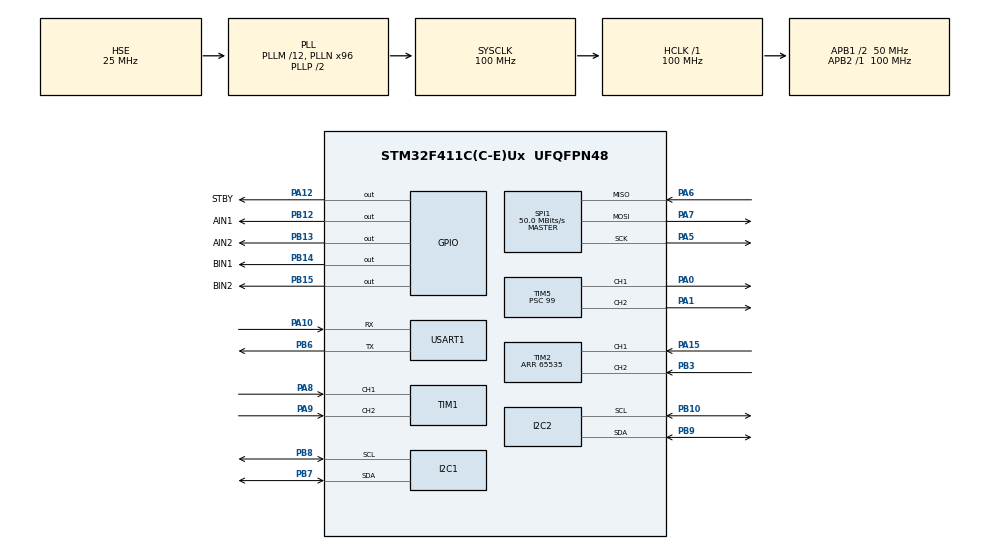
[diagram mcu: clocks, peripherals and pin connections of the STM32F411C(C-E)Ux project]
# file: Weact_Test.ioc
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Dma.I2C2_RX.2.Direction=DMA_PERIPH_TO_MEMORY
Dma.I2C2_RX.2.FIFOMode=DMA_FIFOMODE_DISABLE
Dma.I2C2_RX.2.Instance=DMA1_Stream2
Dma.I2C2_RX.2.MemDataAlignment=DMA_MDATAALIGN_BYTE
Dma.I2C2_RX.2.MemInc=DMA_MINC_ENABLE
Dma.I2C2_RX.2.Mode=DMA_CIRCULAR
Dma.I2C2_RX.2.PeriphDataAlignment=DMA_PDATAALIGN_BYTE
Dma.I2C2_RX.2.PeriphInc=DMA_PINC_DISABLE
Dma.I2C2_RX.2.Priority=DMA_PRIORITY_LOW
Dma.Request0=USART1_RX
Dma.Request1=USART1_TX
Dma.Request2=I2C2_RX
Dma.USART1_RX.0.Direction=DMA_PERIPH_TO_MEMORY
Dma.USART1_RX.0.FIFOMode=DMA_FIFOMODE_DISABLE
Dma.USART1_RX.0.Instance=DMA2_Stream2
Dma.USART1_RX.0.MemDataAlignment=DMA_MDATAALIGN_BYTE
Dma.USART1_RX.0.MemInc=DMA_MINC_ENABLE
Dma.USART1_RX.0.Mode=DMA_NORMAL
Dma.USART1_RX.0.PeriphDataAlignment=DMA_PDATAALIGN_BYTE
Dma.USART1_RX.0.PeriphInc=DMA_PINC_DISABLE
Dma.USART1_RX.0.Priority=DMA_PRIORITY_MEDIUM
Dma.USART1_TX.1.Direction=DMA_MEMORY_TO_PERIPH
Dma.USART1_TX.1.FIFOMode=DMA_FIFOMODE_DISABLE
Dma.USART1_TX.1.Instance=DMA2_Stream7
Dma.USART1_TX.1.MemDataAlignment=DMA_MDATAALIGN_BYTE
Dma.USART1_TX.1.MemInc=DMA_MINC_ENABLE
Dma.USART1_TX.1.Mode=DMA_NORMAL
Dma.USART1_TX.1.PeriphDataAlignment=DMA_PDATAALIGN_BYTE
Dma.USART1_TX.1.PeriphInc=DMA_PINC_DISABLE
Dma.USART1_TX.1.Priority=DMA_PRIORITY_MEDIUM
I2C2.I2C_Mode=I2C_Fast
Mcu.Family=STM32F4
Mcu.Name=STM32F411C(C-E)Ux
Mcu.Package=UFQFPN48
NVIC.DMA1_Stream2_IRQn=true\:0\:0\:false\:false\:true\:false\:true\:true
NVIC.DMA2_Stream2_IRQn=true\:0\:0\:false\:false\:true\:false\:true\:true
NVIC.DMA2_Stream7_IRQn=true\:0\:0\:false\:false\:true\:false\:true\:true
NVIC.PriorityGroup=NVIC_PRIORITYGROUP_4
NVIC.SPI1_IRQn=true\:2\:0\:true\:false\:true\:true\:true\:true
NVIC.TIM1_BRK_TIM9_IRQn=true\:0\:0\:false\:false\:true\:true\:true\:true
NVIC.TIM1_UP_TIM10_IRQn=true\:0\:0\:false\:false\:true\:true\:true\:true
NVIC.TIM2_IRQn=true\:0\:0\:false\:false\:true\:true\:true\:true
NVIC.TIM4_IRQn=true\:0\:0\:false\:false\:true\:true\:true\:true
NVIC.TIM5_IRQn=true\:0\:0\:true\:false\:true\:true\:true\:true
NVIC.USART1_IRQn=true\:2\:0\:true\:false\:true\:true\:true\:true
PA0-WKUP.Signal=S_TIM5_CH1
PA1.Signal=S_TIM5_CH2
PA10.Mode=Asynchronous
PA10.Signal=USART1_RX
PA12.GPIO_Label=STBY
PA12.GPIO_PuPd=GPIO_PULLUP
PA12.Signal=GPIO_Output
PA13.Mode=Serial_Wire
PA13.Signal=SYS_JTMS-SWDIO
PA14.Mode=Serial_Wire
PA14.Signal=SYS_JTCK-SWCLK
PA15.Signal=S_TIM2_CH1_ETR
PA4.GPIO_PuPd=GPIO_PULLUP
PA4.GPIO_Speed=GPIO_SPEED_FREQ_HIGH
PA4.Signal=SPI1_NSS
PA5.Mode=Full_Duplex_Master
PA5.Signal=SPI1_SCK
PA6.Mode=Full_Duplex_Master
PA6.Signal=SPI1_MISO
PA7.Mode=Full_Duplex_Master
PA7.Signal=SPI1_MOSI
PA8.Signal=S_TIM1_CH1
PA9.Signal=S_TIM1_CH2
PB10.Mode=I2C
PB10.Signal=I2C2_SCL
PB12.GPIO_Label=AIN1
PB12.GPIO_PuPd=GPIO_PULLUP
PB12.GPIO_Speed=GPIO_SPEED_FREQ_HIGH
PB12.Signal=GPIO_Output
PB13.GPIO_Label=AIN2
PB13.GPIO_PuPd=GPIO_PULLUP
PB13.GPIO_Speed=GPIO_SPEED_FREQ_HIGH
PB13.Signal=GPIO_Output
PB14.GPIO_Label=BIN1
PB14.GPIO_Speed=GPIO_SPEED_FREQ_HIGH
PB14.Signal=GPIO_Output
PB15.GPIO_Label=BIN2
PB15.GPIO_PuPd=GPIO_PULLUP
PB15.GPIO_Speed=GPIO_SPEED_FREQ_HIGH
PB15.Signal=GPIO_Output
PB3.Signal=S_TIM2_CH2
PB6.Mode=Asynchronous
PB6.Signal=USART1_TX
PB7.Mode=I2C
PB7.Signal=I2C1_SDA
PB8.Mode=I2C
PB8.Signal=I2C1_SCL
PB9.Mode=I2C
PB9.Signal=I2C2_SDA
PC14-OSC32_IN.Mode=LSE-External-Oscillator
PC14-OSC32_IN.Signal=RCC_OSC32_IN
PC15-OSC32_OUT.Mode=LSE-External-Oscillator
PC15-OSC32_OUT.Signal=RCC_OSC32_OUT
PH0\ -\ OSC_IN.Mode=HSE-External-Oscillator
PH0\ -\ OSC_IN.Signal=RCC_OSC_IN
PH1\ -\ OSC_OUT.Mode=HSE-External-Oscillator
PH1\ -\ OSC_OUT.Signal=RCC_OSC_OUT
ProjectManager.HeapSize=0x200
ProjectManager.StackSize=0x400
ProjectManager.TargetToolchain=MDK-ARM V5.32
RCC.48MHZClocksFreq_Value=50000000
RCC.AHBFreq_Value=100000000
RCC.APB1CLKDivider=RCC_HCLK_DIV2
RCC.APB1Freq_Value=50000000
RCC.APB1TimFreq_Value=100000000
RCC.APB2Freq_Value=100000000
RCC.APB2TimFreq_Value=100000000
RCC.CortexFreq_Value=100000000
RCC.HCLKFreq_Value=100000000
RCC.HSE_VALUE=25000000
RCC.HSI_VALUE=16000000
RCC.PLLM=12
RCC.PLLN=96
RCC.PLLSourceVirtual=RCC_PLLSOURCE_HSE
RCC.SYSCLKFreq_VALUE=100000000
RCC.SYSCLKSource=RCC_SYSCLKSOURCE_PLLCLK
RCC.VCOOutputFreq_Value=200000000
SH.S_TIM1_CH1.0=TIM1_CH1,Encoder_Interface
SH.S_TIM1_CH2.0=TIM1_CH2,Encoder_Interface
SH.S_TIM2_CH1_ETR.0=TIM2_CH1,Encoder_Interface
SH.S_TIM2_CH2.0=TIM2_CH2,Encoder_Interface
SH.S_TIM5_CH1.0=TIM5_CH1,PWM Generation1 CH1
SH.S_TIM5_CH2.0=TIM5_CH2,PWM Generation2 CH2
SPI1.CalculateBaudRate=50.0 MBits/s
SPI1.Direction=SPI_DIRECTION_2LINES
SPI1.Mode=SPI_MODE_MASTER
SPI1.VirtualType=VM_MASTER
TIM2.EncoderMode=TIM_ENCODERMODE_TI12
TIM2.Period=65535
TIM4.Period=10000
TIM4.Prescaler=99
TIM5.Channel-PWM\ Generation1\ CH1=TIM_CHANNEL_1
TIM5.Channel-PWM\ Generation2\ CH2=TIM_CHANNEL_2
TIM5.Period=99
TIM5.Prescaler=99
TIM9.Period=5000
TIM9.Prescaler=99
USART1.VirtualMode=VM_ASYNC
VP_TIM4_VS_ClockSourceINT.Mode=Internal
VP_TIM9_VS_ClockSourceINT.Mode=Internal
board=custom

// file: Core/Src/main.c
/* USER CODE BEGIN Header */
/**
  ******************************************************************************
  * @file           : main.c
  * @brief          : Main program body
  ******************************************************************************
  * @attention
  *
  * Copyright (c) 2023 STMicroelectronics.
  * All rights reserved.
  *
  * This software is licensed under terms that can be found in the LICENSE file
  * in the root directory of this software component.
  * If no LICENSE file comes with this software, it is provided AS-IS.
  *
  ******************************************************************************
  */
/* USER CODE END Header */
#include "main.h"
#include "dma.h"
#include "i2c.h"
#include "spi.h"
#include "tim.h"
#include "usart.h"
#include "gpio.h"

/* USER CODE BEGIN Includes */
#include "TB6612.h"
#include "pid.h"
/* USER CODE END Includes */

/* USER CODE BEGIN PM */
uint8_t RxDate[20]={0};
/* USER CODE END PM */

void SystemClock_Config(void);

int main(void)
{

  /* MCU Configuration--------------------------------------------------------*/

  /* Reset of all peripherals, Initializes the Flash interface and the Systick. */
  HAL_Init();

  /* Configure the system clock */
  SystemClock_Config();

  /* Initialize all configured peripherals */
  MX_GPIO_Init();
  MX_DMA_Init();
  MX_SPI1_Init();
  MX_TIM1_Init();
  MX_TIM2_Init();
  MX_USART1_UART_Init();
  MX_I2C1_Init();
  MX_I2C2_Init();
  MX_TIM5_Init();
  MX_TIM4_Init();
  MX_TIM9_Init();
  /* USER CODE BEGIN 2 */
	HAL_TIM_PWM_Init(&htim_pwm);
	HAL_GPIO_WritePin(STBY_GPIO_Port,STBY_Pin,GPIO_PIN_SET);
	HAL_GPIO_WritePin(AIN1_GPIO_Port,AIN1_Pin,GPIO_PIN_SET);
	HAL_GPIO_WritePin(AIN2_GPIO_Port,AIN2_Pin,GPIO_PIN_RESET);
	__HAL_TIM_SetCompare(&htim_pwm,channel_PWMA,99);

  /* USER CODE END 2 */

  /* Infinite loop */
  while (1)
  {

  }
}

void SystemClock_Config(void)
{
  RCC_OscInitTypeDef RCC_OscInitStruct = {0};
  RCC_ClkInitTypeDef RCC_ClkInitStruct = {0};

  /** Configure the main internal regulator output voltage
  */
  __HAL_RCC_PWR_CLK_ENABLE();
  __HAL_PWR_VOLTAGESCALING_CONFIG(PWR_REGULATOR_VOLTAGE_SCALE1);

  /** Initializes the RCC Oscillators according to the specified parameters
  * in the RCC_OscInitTypeDef structure.
  */
  RCC_OscInitStruct.OscillatorType = RCC_OSCILLATORTYPE_HSE;
  RCC_OscInitStruct.HSEState = RCC_HSE_ON;
  RCC_OscInitStruct.PLL.PLLState = RCC_PLL_ON;
  RCC_OscInitStruct.PLL.PLLSource = RCC_PLLSOURCE_HSE;
  RCC_OscInitStruct.PLL.PLLM = 12;
  RCC_OscInitStruct.PLL.PLLN = 96;
  RCC_OscInitStruct.PLL.PLLP = RCC_PLLP_DIV2;
  RCC_OscInitStruct.PLL.PLLQ = 4;
  if (HAL_RCC_OscConfig(&RCC_OscInitStruct) != HAL_OK)
  {
    Error_Handler();
  }

  /** Initializes the CPU, AHB and APB buses clocks
  */
  RCC_ClkInitStruct.ClockType = RCC_CLOCKTYPE_HCLK|RCC_CLOCKTYPE_SYSCLK
                              |RCC_CLOCKTYPE_PCLK1|RCC_CLOCKTYPE_PCLK2;
  RCC_ClkInitStruct.SYSCLKSource = RCC_SYSCLKSOURCE_PLLCLK;
  RCC_ClkInitStruct.AHBCLKDivider = RCC_SYSCLK_DIV1;
  RCC_ClkInitStruct.APB1CLKDivider = RCC_HCLK_DIV2;
  RCC_ClkInitStruct.APB2CLKDivider = RCC_HCLK_DIV1;

  if (HAL_RCC_ClockConfig(&RCC_ClkInitStruct, FLASH_LATENCY_3) != HAL_OK)
  {
    Error_Handler();
  }
}

void Error_Handler(void)
{
  __disable_irq();
  while (1)
  {
  }
}
